# HC32A4A8RITJ register map
File version: 1.0
CPU: CM4 r0p1, little endian, MPU, FPU, 4 interrupt priority bits
Registers are 32-bit, read-write, reset 0x0 unless marked. A register's access mark holds for its fields unless they carry their own. Offsets are from the block's base; [hi:lo] are bit positions; {n}, {i} and the like mark numbered series.

## PERIC
Base 0x40055400
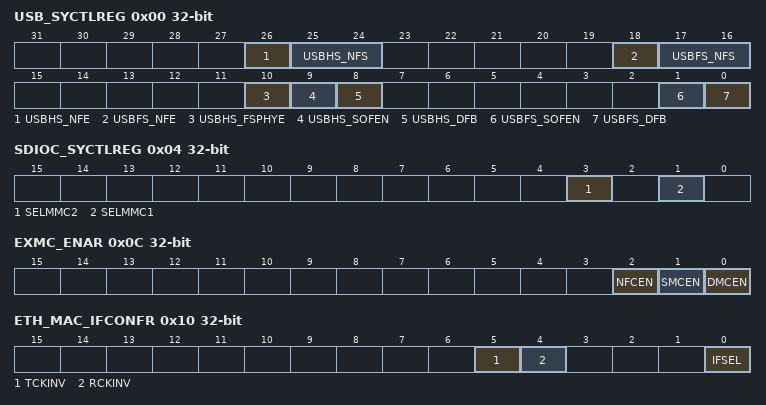
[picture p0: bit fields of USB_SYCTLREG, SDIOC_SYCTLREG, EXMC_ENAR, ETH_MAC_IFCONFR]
0x00 USB_SYCTLREG
  [26] USBHS_NFE, [25:24] USBHS_NFS, [18] USBFS_NFE, [17:16] USBFS_NFS, [10] USBHS_FSPHYE, [9] USBHS_SOFEN, [8] USBHS_DFB, [1] USBFS_SOFEN, [0] USBFS_DFB
0x04 SDIOC_SYCTLREG
  [3] SELMMC2, [1] SELMMC1
0x08 NFC_STCR
  [0] OPENP
0x0C EXMC_ENAR
  [2] NFCEN, [1] SMCEN, [0] DMCEN
0x10 ETH_MAC_IFCONFR
  [5] TCKINV, [4] RCKINV, [0] IFSEL
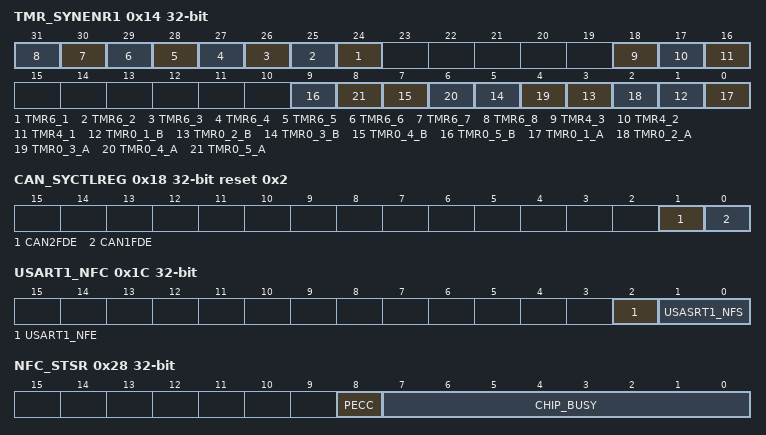
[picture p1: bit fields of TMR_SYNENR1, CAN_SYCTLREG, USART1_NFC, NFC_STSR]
0x14 TMR_SYNENR1
  [n+23] TMR6_{n} (n=1..8), [18] TMR4_3, [17] TMR4_2, [16] TMR4_1, [2n-1] TMR0_{n}_B (n=1..5), [2n-2] TMR0_{n}_A (n=1..5)
0x18 CAN_SYCTLREG reset 0x2
  [1] CAN2FDE, [0] CAN1FDE
0x1C USART1_NFC
  [2] USART1_NFE, [1:0] USASRT1_NFS
0x28 NFC_STSR ro
  [8] PECC, [7:0] CHIP_BUSY
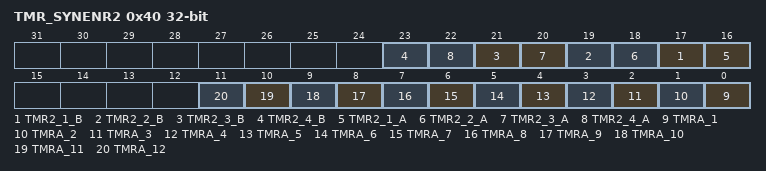
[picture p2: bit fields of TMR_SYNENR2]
0x40 TMR_SYNENR2
  [2n+15] TMR2_{n}_B (n=1..4), [2n+14] TMR2_{n}_A (n=1..4), [n-1] TMRA_{n} (n=1..12)

## PKE
Base 0x4000B000
0x00 RAM0_CKCR
  [1:0] ECCMOD
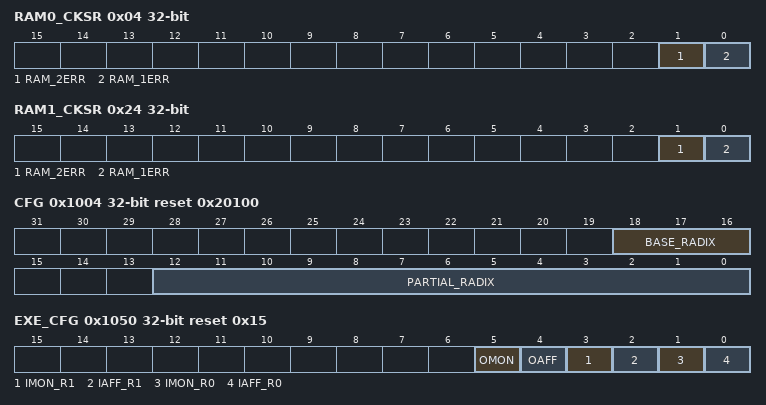
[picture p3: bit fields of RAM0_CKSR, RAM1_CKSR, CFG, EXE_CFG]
0x04 RAM0_CKSR
  [1] RAM_2ERR, [0] RAM_1ERR
0x08 RAM0_EIEN
  [0] EIEN
0x0C RAM0_EIBIT0
0x10 RAM0_EIBIT1
  [6:0] EIBIT1
0x14 RAM0_ECCERRADDR ro
  [12:0] ECCERRADDR
0x20 RAM1_CKCR
  [1:0] ECCMOD
0x24 RAM1_CKSR
  [1] RAM_2ERR, [0] RAM_1ERR
0x28 RAM1_EIEN
  [0] EIEN
0x2C RAM1_EIBIT0
0x30 RAM1_EIBIT1
  [6:0] EIBIT1
0x34 RAM1_ECCERRADDR ro
  [12:0] ECCERRADDR
0x1000 CTRL
  [0] START
0x1004 CFG reset 0x20100
  [18:16] BASE_RADIX, [12:0] PARTIAL_RADIX
0x1008 MC_PTR
  [11:0] ADDR
0x100C RISR
  [0] CORE_RIS
0x1010 IMCR
  [0] CORE_IRQEN
0x1014 MISR ro
  [0] CORE_MI
0x1024 RT_CODE ro
  [3:0] STOP_LOG
0x1050 EXE_CFG reset 0x15
  [5] OMON ro, [4] OAFF, [3] IMON_R1, [2] IAFF_R1, [1] IMON_R0, [0] IAFF_R0
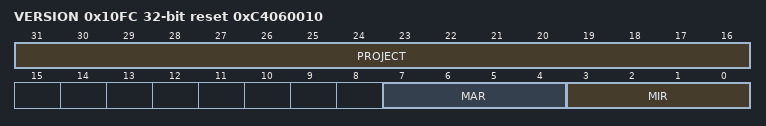
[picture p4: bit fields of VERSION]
0x10FC VERSION ro reset 0xC4060010
  [31:16] PROJECT, [7:4] MAR, [3:0] MIR
0x1400 MEM_RAM0
0x2000 MEM_RAM1

## PWC
Base 0x40048000; alternate view of CMU
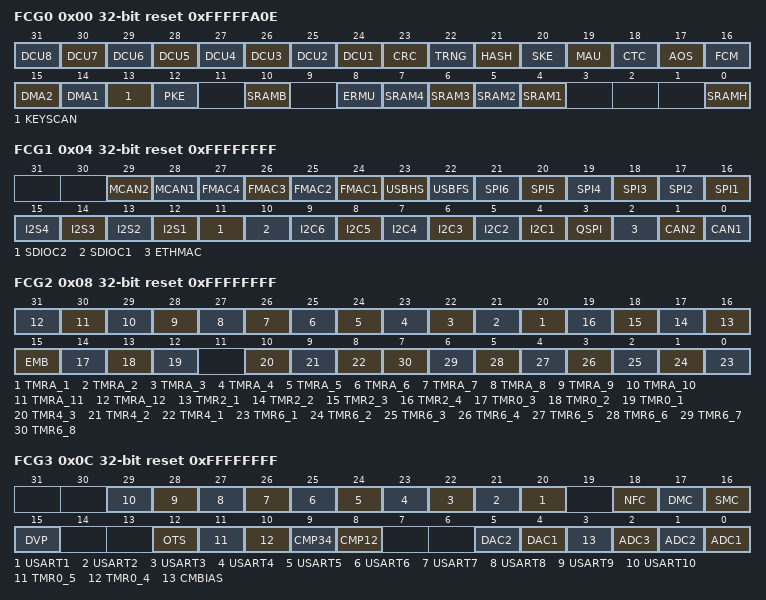
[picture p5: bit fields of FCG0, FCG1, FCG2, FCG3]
0x00 FCG0 reset 0xFFFFFA0E
  [n+23] DCU{n} (n=1..8), [23] CRC, [22] TRNG, [21] HASH, [20] SKE, [19] MAU, [18] CTC, [17] AOS, [16] FCM, [15] DMA2, [14] DMA1, [13] KEYSCAN, [12] PKE, [10] SRAMB, [8] ERMU, [n+3] SRAM{n} (n=1..4), [0] SRAMH
0x04 FCG1 reset 0xFFFFFFFF
  [29] MCAN2, [28] MCAN1, [n+23] FMAC{n} (n=1..4), [23] USBHS, [22] USBFS, [n+15] SPI{n} (n=1..6), [n+11] I2S{n} (n=1..4), [11] SDIOC2, [10] SDIOC1, [n+3] I2C{n} (n=1..6), [3] QSPI, [2] ETHMAC, [1] CAN2, [0] CAN1
0x08 FCG2 reset 0xFFFFFFFF
  [n+19] TMRA_{n} (n=1..12), [n+15] TMR2_{n} (n=1..4), [15] EMB, [14] TMR0_3, [13] TMR0_2, [12] TMR0_1, [10] TMR4_3, [9] TMR4_2, [8] TMR4_1, [n-1] TMR6_{n} (n=1..8)
0x0C FCG3 reset 0xFFFFFFFF
  [n+19] USART{n} (n=1..10), [18] NFC, [17] DMC, [16] SMC, [15] DVP, [12] OTS, [11] TMR0_5, [10] TMR0_4, [9] CMP34, [8] CMP12, [5] DAC2, [4] DAC1, [3] CMBIAS, [2] ADC3, [1] ADC2, [0] ADC1
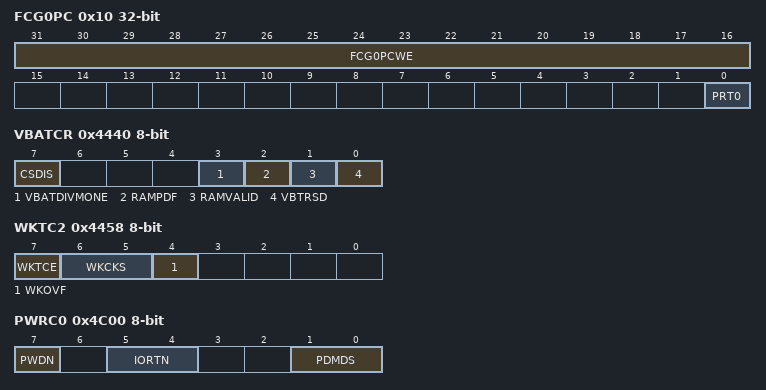
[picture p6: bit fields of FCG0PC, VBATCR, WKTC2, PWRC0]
0x10 FCG0PC
  [31:16] FCG0PCWE wo, [0] PRT0
0x4430 VBATRSTR 8-bit
0x4440 VBATCR 8-bit
  [7] CSDIS, [3] VBATDIVMONE, [2] RAMPDF, [1] RAMVALID, [0] VBTRSD
0x4448 VBATPORF 8-bit ro
  [0] VBATPORF
0x444C VBATPORFCLR 8-bit
  [0] VBATPORFCLR
0x4450 WKTC0 8-bit
  [7:0] WKTMCMP
0x4454 WKTC1 8-bit
  [3:0] WKTMCMP
0x4458 WKTC2 8-bit
  [7] WKTCE, [6:5] WKCKS, [4] WKOVF
{0x4600+4i} BKR{i} 8-bit (i=0..127)
0x4C00 PWRC0 8-bit
  [7] PWDN, [5:4] IORTN, [1:0] PDMDS
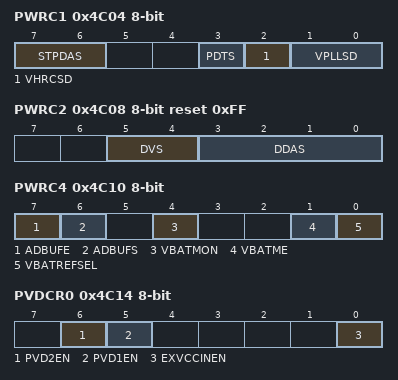
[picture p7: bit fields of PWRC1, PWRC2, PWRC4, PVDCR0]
0x4C04 PWRC1 8-bit
  [7:6] STPDAS, [3] PDTS, [2] VHRCSD, [1:0] VPLLSD
0x4C08 PWRC2 8-bit reset 0xFF
  [5:4] DVS, [3:0] DDAS
0x4C0C PWRC3 8-bit reset 0xFF
0x4C10 PWRC4 8-bit
  [7] ADBUFE, [6] ADBUFS, [4] VBATMON, [1] VBATME, [0] VBATREFSEL
0x4C14 PVDCR0 8-bit
  [6] PVD2EN, [5] PVD1EN, [0] EXVCCINEN
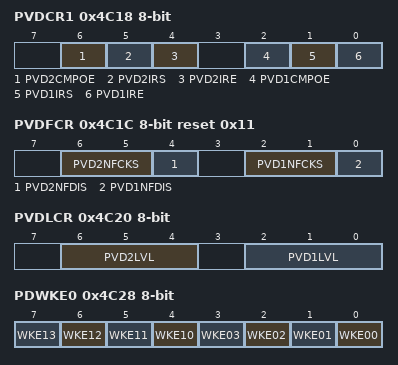
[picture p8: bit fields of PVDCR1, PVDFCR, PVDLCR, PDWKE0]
0x4C18 PVDCR1 8-bit
  [6] PVD2CMPOE, [5] PVD2IRS, [4] PVD2IRE, [2] PVD1CMPOE, [1] PVD1IRS, [0] PVD1IRE
0x4C1C PVDFCR 8-bit reset 0x11
  [6:5] PVD2NFCKS, [4] PVD2NFDIS, [2:1] PVD1NFCKS, [0] PVD1NFDIS
0x4C20 PVDLCR 8-bit
  [6:4] PVD2LVL, [2:0] PVD1LVL
0x4C28 PDWKE0 8-bit
  [n-6] WKE{n} (n=10..13), [n] WKE{n:02} (n=0..3)
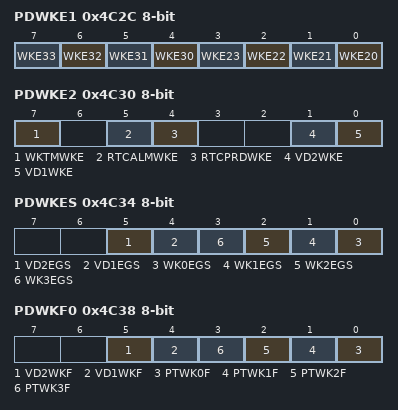
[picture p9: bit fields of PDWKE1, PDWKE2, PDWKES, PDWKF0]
0x4C2C PDWKE1 8-bit
  [n-26] WKE{n} (n=30..33), [n-20] WKE{n} (n=20..23)
0x4C30 PDWKE2 8-bit
  [7] WKTMWKE, [5] RTCALMWKE, [4] RTCPRDWKE, [1] VD2WKE, [0] VD1WKE
0x4C34 PDWKES 8-bit
  [5] VD2EGS, [4] VD1EGS, [n] WK{n}EGS (n=0..3)
0x4C38 PDWKF0 8-bit
  [5] VD2WKF, [4] VD1WKF, [n] PTWK{n}F (n=0..3)
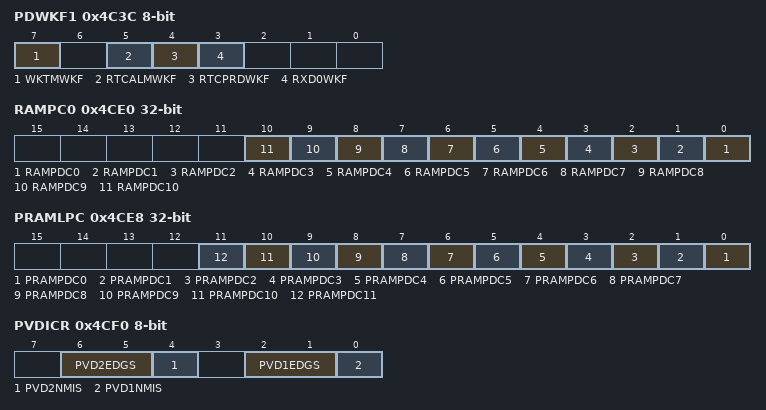
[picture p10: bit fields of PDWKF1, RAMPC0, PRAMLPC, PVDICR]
0x4C3C PDWKF1 8-bit
  [7] WKTMWKF, [5] RTCALMWKF, [4] RTCPRDWKF, [3] RXD0WKF
0x4CE0 RAMPC0
  [n] RAMPDC{n} (n=0..10)
0x4CE4 RAMOPM 16-bit reset 0x8043
0x4CE8 PRAMLPC
  [n] PRAMPDC{n} (n=0..11)
0x4CEC LPMCSR 16-bit ro
  [0] LPMF
0x4CEE LPMCSCR 16-bit
  [0] LPMFC
0x4CF0 PVDICR 8-bit
  [6:5] PVD2EDGS, [4] PVD2NMIS, [2:1] PVD1EDGS, [0] PVD1NMIS
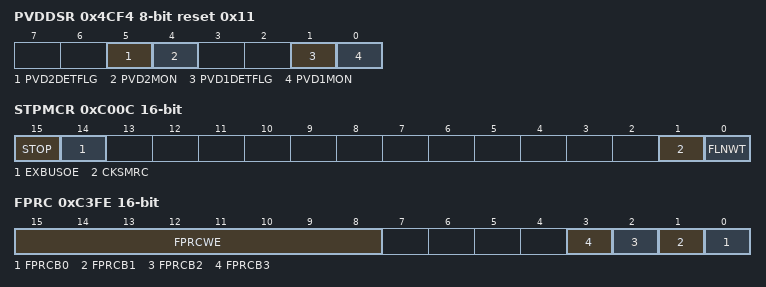
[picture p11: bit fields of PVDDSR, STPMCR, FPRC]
0x4CF4 PVDDSR 8-bit reset 0x11
  [5] PVD2DETFLG, [4] PVD2MON, [1] PVD1DETFLG, [0] PVD1MON
0xC00C STPMCR 16-bit
  [15] STOP, [14] EXBUSOE, [1] CKSMRC, [0] FLNWT
0xC3FE FPRC 16-bit
  [15:8] FPRCWE, [n] FPRCB{n} (n=0..3)
